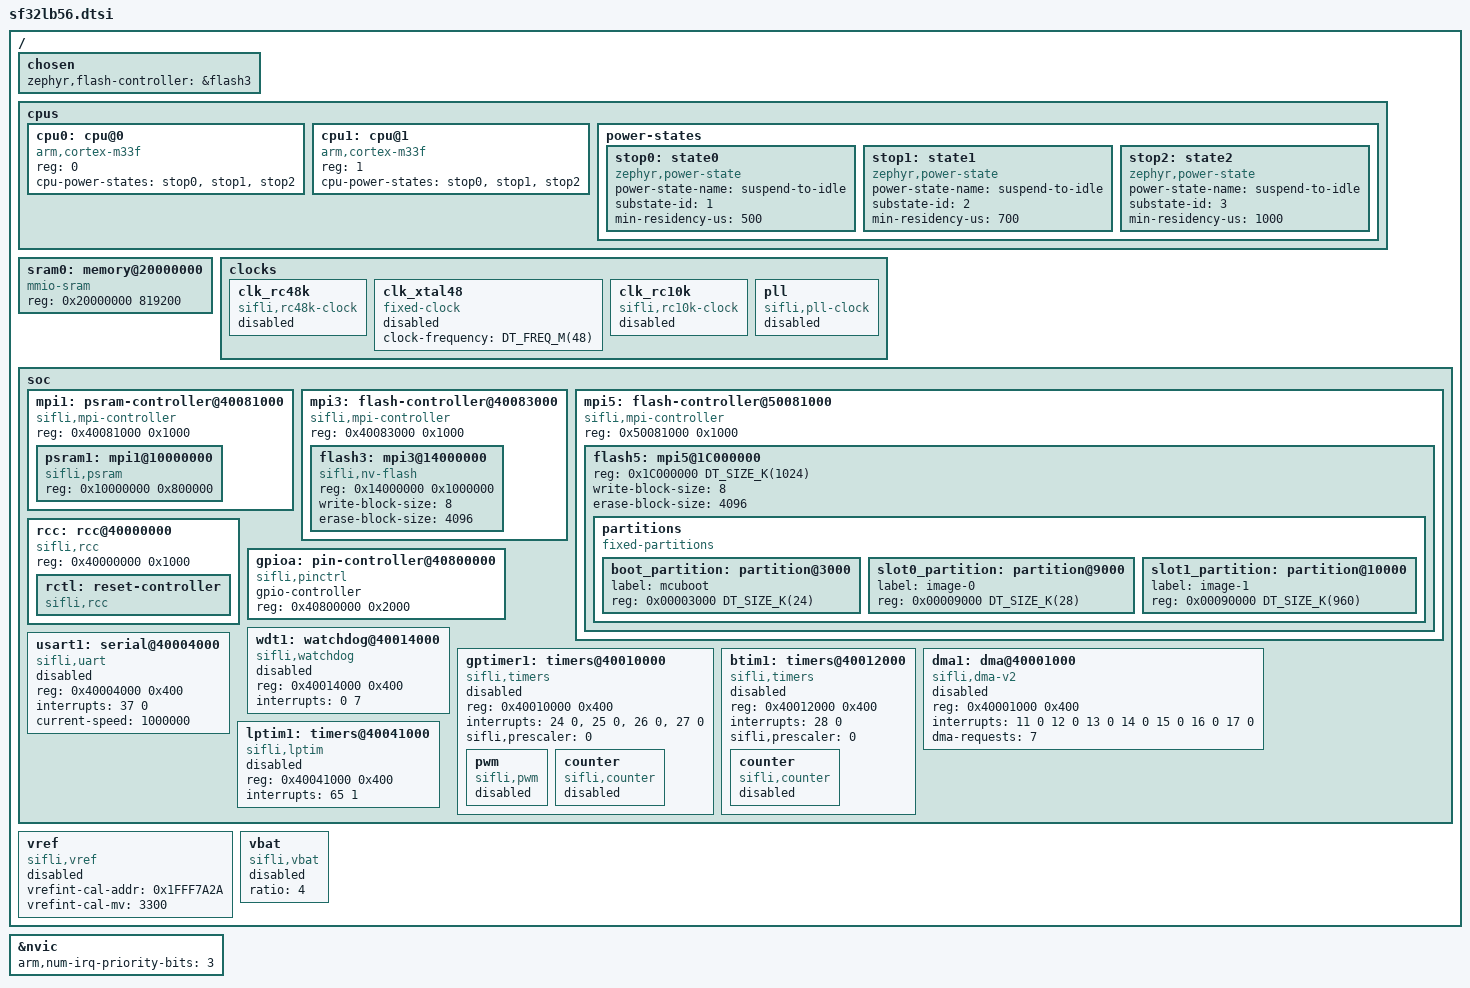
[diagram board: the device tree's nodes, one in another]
/*
 * Copyright (c) 2017 Linaro Limited
 * Copyright (c) 2019 Centaur Analytics, Inc
 * Copyright (c) 2024 STMicroelectronics
 *
 * SPDX-License-Identifier: Apache-2.0
 */


#include <arm/armv8-m.dtsi>
#include <zephyr/dt-bindings/i2c/i2c.h>
#include <zephyr/dt-bindings/gpio/gpio.h>
#include <zephyr/dt-bindings/pwm/pwm.h>
#include <zephyr/dt-bindings/adc/adc.h>
#include <freq.h>
#include <mem.h>

#define SF32LB_CLOCK(a,b)
#define SF32LB_RESET(a,b)
#define SF32LB_SRC_MSI 
#define CLK48_SEL(a)

/ {
	chosen {
		//zephyr,entropy = &rng1;
		zephyr,flash-controller = &flash3;
	};

	cpus {
		#address-cells = <1>;
		#size-cells = <0>;

		cpu0: cpu@0 {
			device_type = "cpu";
			compatible = "arm,cortex-m33f";
			reg = <0>;
			cpu-power-states = <&stop0 &stop1 &stop2>;
		};

		cpu1: cpu@1 {
			device_type = "cpu";
			compatible = "arm,cortex-m33f";
			reg = <1>;
			cpu-power-states = <&stop0 &stop1 &stop2>;
		};

		power-states {
			stop0: state0 {
				compatible = "zephyr,power-state";
				power-state-name = "suspend-to-idle";
				substate-id = <1>;
				min-residency-us = <500>;
			};
			stop1: state1 {
				compatible = "zephyr,power-state";
				power-state-name = "suspend-to-idle";
				substate-id = <2>;
				min-residency-us = <700>;
			};
			stop2: state2 {
				compatible = "zephyr,power-state";
				power-state-name = "suspend-to-idle";
				substate-id = <3>;
				min-residency-us = <1000>;
			};
		};
	};

	sram0: memory@20000000 {
		compatible = "mmio-sram";
        reg = <0x20000000 819200>;
	};

	clocks {
		clk_rc48k: clk_rc48k {
			#clock-cells = <0>;
			compatible = "sifli,rc48k-clock";
			status = "enabled";
		};

		clk_xtal48: clk_xtal48 {
			#clock-cells = <0>;
			compatible = "fixed-clock";
			clock-frequency = <DT_FREQ_M(48)>;
			status = "disabled";
		};

		clk_rc10k: clk_rc10k {
			#clock-cells = <0>;
			compatible = "sifli,rc10k-clock";
			status = "disabled";
		};

		pll: pll {
			#clock-cells = <0>;
			compatible = "sifli,pll-clock";
			status = "disabled";
		};
	};

	soc {
		mpi1: psram-controller@40081000 {
			compatible = "sifli,mpi-controller", "sifli,sf32lb56-flash-controller";
			reg = <0x40081000 0x1000>;
			//clocks = <&rcc SF32LB_CLOCK(AHB1, 8U)>;

			#address-cells = <1>;
			#size-cells = <1>;

			psram1: mpi1@10000000 {
				compatible = "sifli,psram", "soc-psram";
                reg = <0x10000000 0x800000>;
			};
		};
		mpi3: flash-controller@40083000 {
			compatible = "sifli,mpi-controller", "sifli,sf32lb56-flash-controller";
			reg = <0x40083000 0x1000>;
			//clocks = <&rcc SF32LB_CLOCK(AHB1, 8U)>;

			#address-cells = <1>;
			#size-cells = <1>;

			flash3: mpi3@14000000 {
				compatible = "sifli,nv-flash", "soc-nv-flash";
                reg = <0x14000000 0x1000000>;
				write-block-size = <8>;
				erase-block-size = <4096>;				
			};
		};
		mpi5: flash-controller@50081000 {
			compatible = "sifli,mpi-controller", "sifli,sf32lb56-flash-controller";
			reg = <0x50081000 0x1000>;
			//clocks = <&rcc SF32LB_CLOCK(AHB1, 8U)>;

			#address-cells = <1>;
			#size-cells = <1>;

			flash5: mpi5@1C000000 {
                reg = <0x1C000000 DT_SIZE_K(1024)>;
				write-block-size = <8>;
				erase-block-size = <4096>;
                partitions {
                    compatible = "fixed-partitions";
                    #address-cells = <1>;
                    #size-cells = <1>;
                    boot_partition: partition@3000 {
                        label = "mcuboot";
                        reg = <0x00003000 DT_SIZE_K(24)>;
                    };
                    slot0_partition: partition@9000 {
                        label = "image-0";
                        reg = <0x00009000 DT_SIZE_K(28)>;
                    };     
                    slot1_partition: partition@10000 {
                        label = "image-1";
                        reg = <0x00090000 DT_SIZE_K(960)>;
                    };                      
                };                
			};
		};        
		rcc: rcc@40000000 {
			compatible = "sifli,rcc";
			#clock-cells = <2>;
			reg = <0x40000000 0x1000>;

			rctl: reset-controller {
				compatible = "sifli,rcc";
				#reset-cells = <1>;
			};
		};

		gpioa: pin-controller@40800000 {
			compatible = "sifli,pinctrl";
			gpio-controller;
            #gpio-cells = <2>;
			reg = <0x40800000 0x2000>;
            //clocks = <&rcc SF32LB_CLOCK(AHB2, 0U)>;
		};

		wdt1: watchdog@40014000 {
			compatible = "sifli,watchdog";
			reg = <0x40014000 0x400>;
			status = "disabled";
			//clocks = <&rcc SF32LB_CLOCK(APB1, 11U)>;
			interrupts = <0 7>;
		};

		usart1: serial@40004000 {
			compatible = "sifli,uart";
			reg = <0x40004000 0x400>;
			//clocks = <&rcc SF32LB_CLOCK(APB2, 14U)>;
			//resets = <&rctl SF32LB_RESET(APB2, 14U)>;
			interrupts = <37 0>;
			current-speed = <1000000>;
			status = "disabled";
		};

		gptimer1: timers@40010000 {
			compatible = "sifli,timers";
			reg = <0x40010000 0x400>;
			//clocks = <&rcc SF32LB_CLOCK(APB2, 11U)>;
			//resets = <&rctl SF32LB_RESET(APB2, 11U)>;
			interrupts = <24 0>, <25 0>, <26 0>, <27 0>;
			interrupt-names = "brk", "up", "trgcom", "cc";
			sifli,prescaler = <0>;
			status = "disabled";

			pwm {
				compatible = "sifli,pwm";
				status = "disabled";
				#pwm-cells = <3>;
			};
			counter {
				compatible = "sifli,counter";
				status = "disabled";
			};
		};

		btim1: timers@40012000 {
			compatible = "sifli,timers";
			reg = <0x40012000 0x400>;
			//clocks = <&rcc SF32LB_CLOCK(APB1, 0U)>;
			//resets = <&rctl SF32LB_RESET(APB1L, 0U)>;
			interrupts = <28 0>;
			interrupt-names = "global";
			sifli,prescaler = <0>;
			status = "disabled";

			counter {
				compatible = "sifli,counter";
				status = "disabled";
			};
		};

		dma1: dma@40001000 {
			compatible = "sifli,dma-v2";
			#dma-cells = <3>;
			reg = <0x40001000 0x400>;
			interrupts = <11 0 12 0 13 0 14 0 15 0 16 0 17 0>;
			//clocks = <&rcc SF32LB_CLOCK(AHB1, 0U)>;
			dma-requests = <7>;
			status = "disabled";
		};

		lptim1: timers@40041000 {
			compatible = "sifli,lptim";
			//clocks = <&rcc SF32LB_CLOCK(APB1, 31U)>;
			#address-cells = <1>;
			#size-cells = <0>;
			reg = <0x40041000 0x400>;
			interrupts = <65 1>;
			interrupt-names = "wakeup";
			status = "disabled";
		};

		//rng1: rng@4000F000 {
		//	compatible = "sifli,rng";
		//	reg = <0x4000F000 0x400>;
		//	interrupts = <80 0>;
			//clocks = <&rcc SF32LB_CLOCK(AHB2, 18U)>,
				/* Following domain clock setting requires MSI
				 * clock to be enabled with msi-range = <11>;
				 */
            //<&rcc SF32LB_SRC_MSI CLK48_SEL(3)>;
		//	status = "disabled";
		//};

		//pmuc: power@5004A000 {
		//	compatible = "sifli,pmuc";
		//	reg = <0x5004A000 0x400>; /* PWR register bank */
		//	status = "disabled";

		//	wkup-pins-nb = <5>; /* 5 system wake-up pins */
		//	wkup-pins-pol;
		//	wkup-pins-pupd;

		//	#address-cells = <1>;
		//	#size-cells = <0>;

		//	wkup-pin@1 {
		//		reg = <0x1>;
		//	};

		//	wkup-pin@2 {
		//		reg = <0x2>;
		//	};

		//	wkup-pin@3 {
		//		reg = <0x3>;
		//	};

		//	wkup-pin@4 {
		//		reg = <0x4>;
		//	};

		//	wkup-pin@5 {
		//		reg = <0x5>;
		//	};
		//};
	};
  	vref: vref {
		compatible = "sifli,vref";
		vrefint-cal-addr = <0x1FFF7A2A>;
		vrefint-cal-mv = <3300>;
		//io-channels = <&adc1 17>;
		status = "disabled";
	};

	vbat: vbat {
		compatible = "sifli,vbat";
		ratio = <4>;
		//io-channels = <&adc1 18>;
		status = "disabled";
	};

};

&nvic {
	arm,num-irq-priority-bits = <3>;
};
